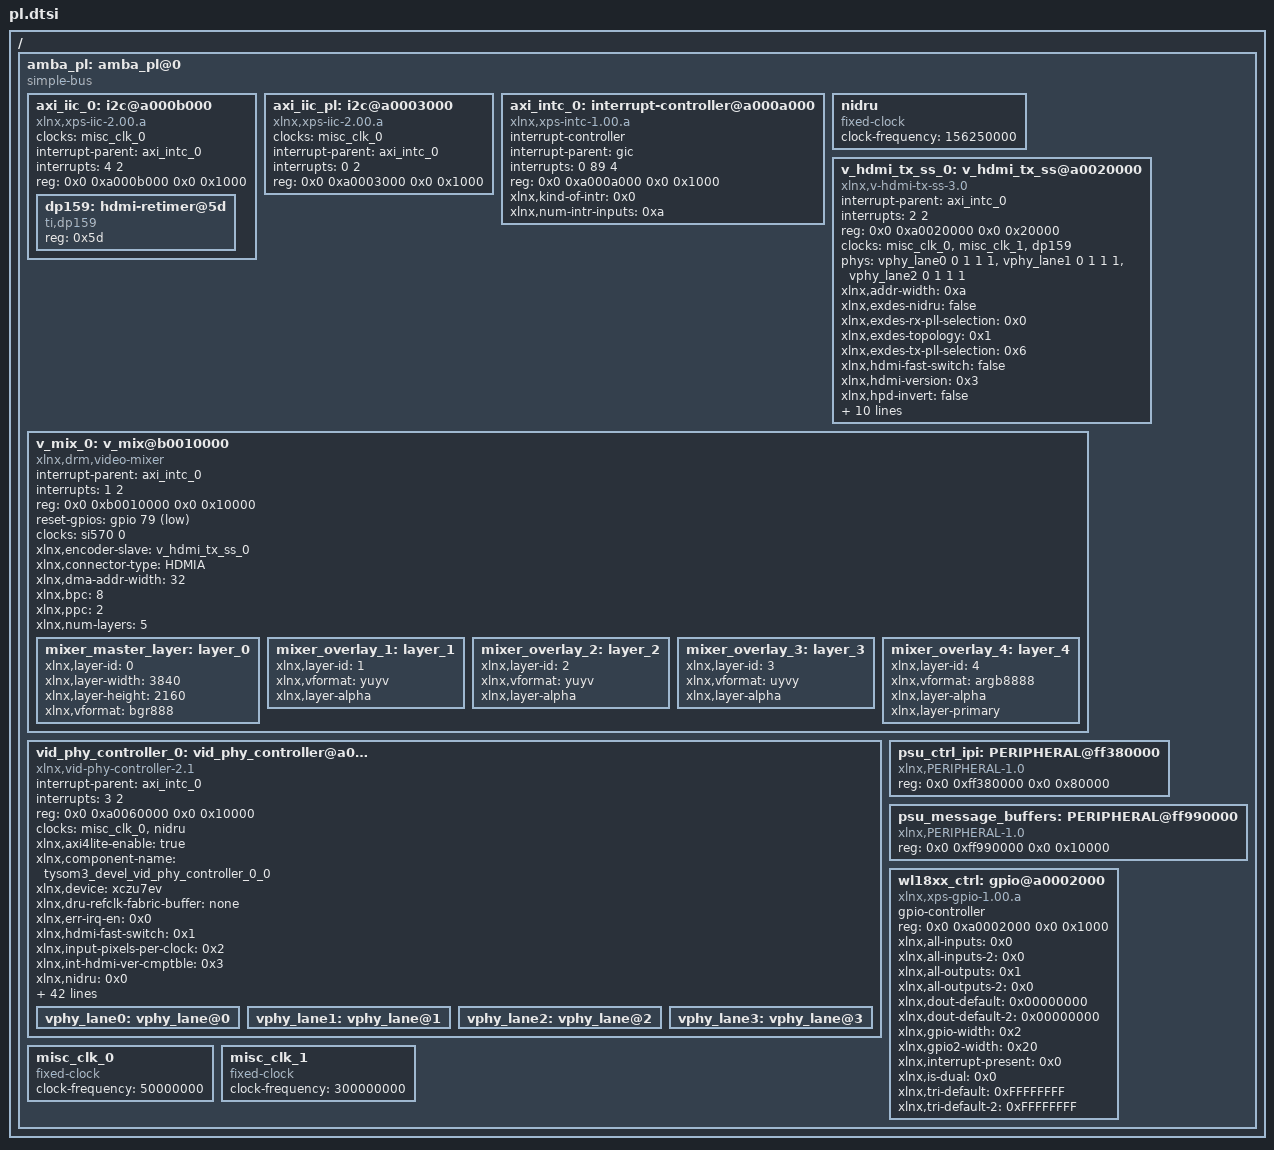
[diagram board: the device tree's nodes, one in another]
/*
 * CAUTION: This file is automatically generated by Xilinx.
 * Version:  
 * Today is: Wed Nov  8 10:41:27 2017
 */


/ {
	amba_pl: amba_pl@0 {
		#address-cells = <2>;
		#size-cells = <2>;
		compatible = "simple-bus";
		ranges;
		
		axi_iic_0: i2c@a000b000 {
			#address-cells = <1>;
			#size-cells = <0>;
			clocks = <&misc_clk_0>;
			compatible = "xlnx,xps-iic-2.00.a";
			interrupt-parent = <&axi_intc_0>;
			interrupts = <4 2>;
			reg = <0x0 0xa000b000 0x0 0x1000>;
			
			dp159: hdmi-retimer@5d {
				status = "okay";
				compatible = "ti,dp159";
				reg = <0x5d>;
				#address-cells = <1>;
				#size-cells = <0>;
				#clock-cells = <0>;
			};
		};
		
		axi_iic_pl: i2c@a0003000 {
			#address-cells = <1>;
			#size-cells = <0>;
			clocks = <&misc_clk_0>;
			compatible = "xlnx,xps-iic-2.00.a";
			interrupt-parent = <&axi_intc_0>;
			interrupts = <0 2>;
			reg = <0x0 0xa0003000 0x0 0x1000>;
		};
		
		axi_intc_0: interrupt-controller@a000a000 {
			#interrupt-cells = <2>;
			compatible = "xlnx,xps-intc-1.00.a";
			interrupt-controller ;
			interrupt-parent = <&gic>;
			interrupts = <0 89 4>;
			reg = <0x0 0xa000a000 0x0 0x1000>;
			xlnx,kind-of-intr = <0x0>;
			xlnx,num-intr-inputs = <0xa>;
		};
		
		nidru: nidru {
			compatible = "fixed-clock";
			#clock-cells = <0x0>;
			clock-frequency = <156250000>;
		};
		
		v_hdmi_tx_ss_0: v_hdmi_tx_ss@a0020000 {
			compatible = "xlnx,v-hdmi-tx-ss-3.0";
			interrupt-parent = <&axi_intc_0>;
			interrupts = <2 2>;
			interrupt-names = "hdmitx";
			reg = <0x0 0xa0020000 0x0 0x20000>;
			reg-names = "hdmi-txss";
			clocks = <&misc_clk_0>, <&misc_clk_1>, <&dp159>;
			clock-names = "axi-lite", "video", "retimer-clk";
			phy-names = "hdmi-phy0", "hdmi-phy1", "hdmi-phy2";
			phys = <&vphy_lane0 0 1 1 1>, <&vphy_lane1 0 1 1 1>, <&vphy_lane2 0 1 1 1>;
			xlnx,addr-width = <0xa>;
			xlnx,exdes-nidru = "false";
			xlnx,exdes-rx-pll-selection = <0x0>;
			xlnx,exdes-topology = <0x1>;
			xlnx,exdes-tx-pll-selection = <0x6>;
			xlnx,hdmi-fast-switch = "false";
			xlnx,hdmi-version = <0x3>;
			xlnx,hpd-invert = "false";
			xlnx,hysteresis-level = <0xc>;
			xlnx,include-low-reso-vid = "false";
			xlnx,include-yuv420-sup = "true";
			xlnx,input-pixels-per-clock = <0x2>;
			xlnx,max-bits-per-component = <0x8>;
			xlnx,validation-enable = "false";
			xlnx,vid-interface = <0x0>;
			xlnx,video-mask-enable = <0x1>;
			xlnx,hdcp-authenticate = <0x0>;
			xlnx,hdcp-encrypt = <0x0>;
		};
		
		v_mix_0: v_mix@b0010000 {
			compatible = "xlnx,drm,video-mixer";
			interrupt-parent = <&axi_intc_0>;
			interrupts = <1 2>;
			reg = <0x0 0xb0010000 0x0 0x10000>;
			reset-gpios = <&gpio 79 1>;
			clocks = <&si570 0>;
			xlnx,encoder-slave = <&v_hdmi_tx_ss_0>;
			xlnx,connector-type = "HDMIA";
			xlnx,dma-addr-width=<32>;
			xlnx,bpc = <8>;
			xlnx,ppc = <2>;
			xlnx,num-layers = <5>;
			mixer_master_layer: layer_0 {
				xlnx,layer-id = <0>;
				xlnx,layer-width = <3840>;
				xlnx,layer-height = <2160>;
				xlnx,vformat = "bgr888";
			};
			mixer_overlay_1: layer_1 {
				xlnx,layer-id = <1>;
				xlnx,vformat = "yuyv";
				xlnx,layer-alpha;
			};
			mixer_overlay_2: layer_2 {
				xlnx,layer-id = <2>;
				xlnx,vformat = "yuyv";
				xlnx,layer-alpha;
			};
			mixer_overlay_3: layer_3 {
				xlnx,layer-id = <3>;
				xlnx,vformat = "uyvy";
				xlnx,layer-alpha;
			};
			mixer_overlay_4: layer_4 {
				xlnx,layer-id = <4>;
				xlnx,vformat = "argb8888";
				xlnx,layer-alpha;
				xlnx,layer-primary;
			};
		};
		
		vid_phy_controller_0: vid_phy_controller@a0060000 {
			compatible = "xlnx,vid-phy-controller-2.1";
			interrupt-parent = <&axi_intc_0>;
			interrupts = <3 2>;
			reg = <0x0 0xa0060000 0x0 0x10000>;
			clocks = <&misc_clk_0>, <&nidru>;
			clock-names = "axi-lite", "dru-clk";
			xlnx,axi4lite-enable = "true";
			xlnx,component-name = "tysom3_devel_vid_phy_controller_0_0";
			xlnx,device = "xczu7ev";
			xlnx,dru-refclk-fabric-buffer = "none";
			xlnx,err-irq-en = <0x0>;
			xlnx,hdmi-fast-switch = <0x1>;
			xlnx,input-pixels-per-clock = <0x2>;
			xlnx,int-hdmi-ver-cmptble = <0x3>;
			xlnx,nidru = <0x0>;
			xlnx,nidru-refclk-sel = <0x0>;
			xlnx,rx-gt-debug-ports = "false";
			xlnx,rx-no-of-channels = <0x3>;
			xlnx,rx-outclk-buffer = "none";
			xlnx,rx-pll-selection = <0x0>;
			xlnx,rx-protocol = <0x3>;
			xlnx,rx-refclk-sel = <0x1>;
			xlnx,rx-sb-ports = "true";
			xlnx,rx-tmds-clk-buffer = "bufg";
			xlnx,rx-video-clk-buffer = "bufg";
			xlnx,silicon-revision = <0x0>;
			xlnx,supportlevel = <0x1>;
			xlnx,transceivercontrol = "false";
			xlnx,tx-gt-debug-ports = "false";
			xlnx,tx-no-of-channels = <0x3>;
			xlnx,tx-outclk-buffer = "none";
			xlnx,tx-pll-selection = <0x6>;
			xlnx,tx-protocol = <0x1>;
			xlnx,tx-refclk-fabric-buffer = "none";
			xlnx,tx-refclk-sel = <0x0>;
			xlnx,tx-sb-ports = "true";
			xlnx,tx-tmds-clk-buffer = "bufg";
			xlnx,tx-video-clk-buffer = "bufg";
			xlnx,txpi-port-en = "false";
			xlnx,txrefclk-rdy-invert = <0x1>;
			xlnx,use-oddr-for-tmds-clkout = "true";
			xlnx,vid-phy-axi4lite-addr-width = <0xa>;
			xlnx,vid-phy-axi4lite-data-width = <0x20>;
			xlnx,vid-phy-control-sb-rx-tdata-width = <0x1>;
			xlnx,vid-phy-control-sb-tx-tdata-width = <0x1>;
			xlnx,vid-phy-rx-axi4s-ch-int-tdata-width = <0x14>;
			xlnx,vid-phy-rx-axi4s-ch-tdata-width = <0x14>;
			xlnx,vid-phy-rx-axi4s-ch-tuser-width = <0x1>;
			xlnx,vid-phy-status-sb-rx-tdata-width = <0x1>;
			xlnx,vid-phy-status-sb-tx-tdata-width = <0x2>;
			xlnx,vid-phy-tx-axi4s-ch-int-tdata-width = <0x14>;
			xlnx,vid-phy-tx-axi4s-ch-tdata-width = <0x14>;
			xlnx,vid-phy-tx-axi4s-ch-tuser-width = <0x1>;
			xlnx,viper-reg = "false";
			xlnx,transceiver-type = <0x5>;
			xlnx,tx-buffer-bypass = <0x1>;
			xlnx,transceiver-width = <2>;
			vphy_lane0: vphy_lane@0 {
				#phy-cells = <4>;
			};
			vphy_lane1: vphy_lane@1 {
				#phy-cells = <4>;
			};
			vphy_lane2: vphy_lane@2 {
				#phy-cells = <4>;
			};
			vphy_lane3: vphy_lane@3 {
				#phy-cells = <4>;
			};
		};
		
		psu_ctrl_ipi: PERIPHERAL@ff380000 {
			compatible = "xlnx,PERIPHERAL-1.0";
			reg = <0x0 0xff380000 0x0 0x80000>;
		};
		
		psu_message_buffers: PERIPHERAL@ff990000 {
			compatible = "xlnx,PERIPHERAL-1.0";
			reg = <0x0 0xff990000 0x0 0x10000>;
		};
		
		wl18xx_ctrl: gpio@a0002000 {
			#gpio-cells = <2>;
			compatible = "xlnx,xps-gpio-1.00.a";
			gpio-controller ;
			reg = <0x0 0xa0002000 0x0 0x1000>;
			xlnx,all-inputs = <0x0>;
			xlnx,all-inputs-2 = <0x0>;
			xlnx,all-outputs = <0x1>;
			xlnx,all-outputs-2 = <0x0>;
			xlnx,dout-default = <0x00000000>;
			xlnx,dout-default-2 = <0x00000000>;
			xlnx,gpio-width = <0x2>;
			xlnx,gpio2-width = <0x20>;
			xlnx,interrupt-present = <0x0>;
			xlnx,is-dual = <0x0>;
			xlnx,tri-default = <0xFFFFFFFF>;
			xlnx,tri-default-2 = <0xFFFFFFFF>;
		};
		
		misc_clk_0: misc_clk_0 {
			#clock-cells = <0>;
			clock-frequency = <50000000>;
			compatible = "fixed-clock";
		};
		
		misc_clk_1: misc_clk_1 {
			#clock-cells = <0>;
			clock-frequency = <300000000>;
			compatible = "fixed-clock";
		};
	};
};
